# AT90USB1287 device description
Architecture: AVR8; Family: megaAVR
Registers are 8-bit, access not given, no defined reset value unless marked. A register's access mark holds for its fields unless they carry their own. Offsets are from the block's base; [hi:lo] are bit positions; {n}, {i} and the like mark numbered series; 'fields as' and 'values as' point back to an identical list.

## TC3 (TC16 module) — Timer/Counter, 16-bit
Instances: TC3 0x00
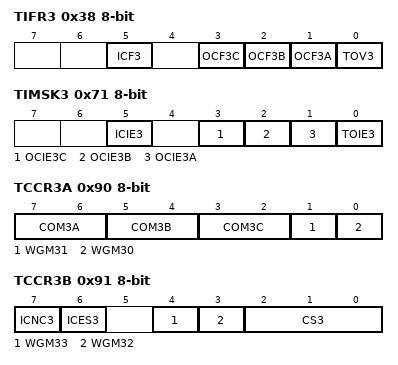
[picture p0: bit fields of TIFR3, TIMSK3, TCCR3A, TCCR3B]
0x38 TIFR3 — Timer/Counter3 Interrupt Flag register
  [5] ICF3 — Input Capture Flag 3
  [3] OCF3C — Output Compare Flag 3C
  [2] OCF3B — Output Compare Flag 3B
  [1] OCF3A — Output Compare Flag 3A
  [0] TOV3 — Timer/Counter3 Overflow Flag
0x71 TIMSK3 — Timer/Counter3 Interrupt Mask Register
  [5] ICIE3 — Timer/Counter3 Input Capture Interrupt Enable
  [3] OCIE3C — Timer/Counter3 Output Compare C Match Interrupt Enable
  [2] OCIE3B — Timer/Counter3 Output Compare B Match Interrupt Enable
  [1] OCIE3A — Timer/Counter3 Output Compare A Match Interrupt Enable
  [0] TOIE3 — Timer/Counter3 Overflow Interrupt Enable
0x90 TCCR3A — Timer/Counter3 Control Register A
  [7:6] COM3A — Compare Output Mode 1A, bits
  [5:4] COM3B — Compare Output Mode 3B, bits
  [3:2] COM3C — Compare Output Mode 3C, bits
  [1] WGM31 — Waveform Generation Mode
  [0] WGM30 — Waveform Generation Mode
0x91 TCCR3B — Timer/Counter3 Control Register B
  [7] ICNC3 — Input Capture 3 Noise Canceler
  [6] ICES3 — Input Capture 3 Edge Select
  [4] WGM33 (bit 2 of the value upward) — Waveform Generation Mode
  [3] WGM32 (bit 2 of the value upward) — Waveform Generation Mode
  [2:0] CS3 — Prescaler source of Timer/Counter 3
    0=No Clock Source (Stopped); 1=Running, No Prescaling; 2=Running, CLK/8; 3=Running, CLK/64; 4=Running, CLK/256; 5=Running, CLK/1024; 6=Running, ExtClk Tx Falling Edge; 7=Running, ExtClk Tx Rising Edge
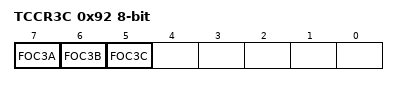
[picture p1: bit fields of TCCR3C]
0x92 TCCR3C — Timer/Counter 3 Control Register C
  [7] FOC3A — Force Output Compare 3A
  [6] FOC3B — Force Output Compare 3B
  [5] FOC3C — Force Output Compare 3C
0x94 TCNT3 16-bit — Timer/Counter3 Bytes
0x96 ICR3 16-bit — Timer/Counter3 Input Capture Register Bytes
0x98 OCR3A 16-bit — Timer/Counter3 Output Compare Register A Bytes
0x9A OCR3B 16-bit — Timer/Counter3 Output Compare Register B Bytes
0x9C OCR3C 16-bit — Timer/Counter3 Output Compare Register B Bytes

## TC1 (TC16 module) — Timer/Counter, 16-bit
Instances: TC1 0x00
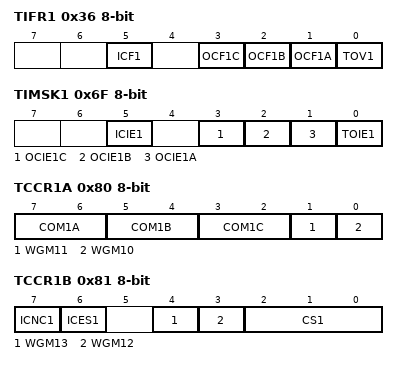
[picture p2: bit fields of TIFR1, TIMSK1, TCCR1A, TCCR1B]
0x36 TIFR1 — Timer/Counter1 Interrupt Flag register
  [5] ICF1 — Input Capture Flag 1
  [3] OCF1C — Output Compare Flag 1C
  [2] OCF1B — Output Compare Flag 1B
  [1] OCF1A — Output Compare Flag 1A
  [0] TOV1 — Timer/Counter1 Overflow Flag
0x6F TIMSK1 — Timer/Counter1 Interrupt Mask Register
  [5] ICIE1 — Timer/Counter1 Input Capture Interrupt Enable
  [3] OCIE1C — Timer/Counter1 Output Compare C Match Interrupt Enable
  [2] OCIE1B — Timer/Counter1 Output Compare B Match Interrupt Enable
  [1] OCIE1A — Timer/Counter1 Output Compare A Match Interrupt Enable
  [0] TOIE1 — Timer/Counter1 Overflow Interrupt Enable
0x80 TCCR1A — Timer/Counter1 Control Register A
  [7:6] COM1A — Compare Output Mode 1A, bits
  [5:4] COM1B — Compare Output Mode 1B, bits
  [3:2] COM1C — Compare Output Mode 1C, bits
  [1] WGM11 — Waveform Generation Mode
  [0] WGM10 — Waveform Generation Mode
0x81 TCCR1B — Timer/Counter1 Control Register B
  [7] ICNC1 — Input Capture 1 Noise Canceler
  [6] ICES1 — Input Capture 1 Edge Select
  [4] WGM13 (bit 2 of the value upward) — Waveform Generation Mode
  [3] WGM12 (bit 2 of the value upward) — Waveform Generation Mode
  [2:0] CS1 — Prescaler source of Timer/Counter 1
    0=No Clock Source (Stopped); 1=Running, No Prescaling; 2=Running, CLK/8; 3=Running, CLK/64; 4=Running, CLK/256; 5=Running, CLK/1024; 6=Running, ExtClk Tx Falling Edge; 7=Running, ExtClk Tx Rising Edge
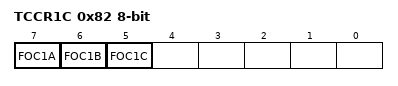
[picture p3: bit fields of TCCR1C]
0x82 TCCR1C — Timer/Counter 1 Control Register C
  [7] FOC1A — Force Output Compare 1A
  [6] FOC1B — Force Output Compare 1B
  [5] FOC1C — Force Output Compare 1C
0x84 TCNT1 16-bit — Timer/Counter1 Bytes
0x86 ICR1 16-bit — Timer/Counter1 Input Capture Register Bytes
0x88 OCR1A 16-bit — Timer/Counter1 Output Compare Register A Bytes
0x8A OCR1B 16-bit — Timer/Counter1 Output Compare Register B Bytes
0x8C OCR1C 16-bit — Timer/Counter1 Output Compare Register C Bytes

## JTAG — JTAG Interface
Instances: JTAG 0x00
0x51 OCDR — On-Chip Debug Related Register in I/O Memory
0x54 MCUSR — MCU Status Register
  [4] JTRF — JTAG Reset Flag
0x55 MCUCR — MCU Control Register
  [7] JTD — JTAG Interface Disable

## EXINT — External Interrupts
Instances: EXINT 0x00
0x3B PCIFR — Pin Change Interrupt Flag Register
  [0] PCIF0 — Pin Change Interrupt Flag 0
0x3C EIFR — External Interrupt Flag Register
  [7:0] INTF — External Interrupt Flags
0x3D EIMSK — External Interrupt Mask Register
  [7:0] INT — External Interrupt Request 7 Enable
0x68 PCICR — Pin Change Interrupt Control Register
  [0] PCIE0 — Pin Change Interrupt Enable 0
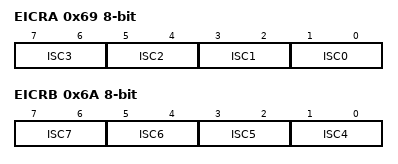
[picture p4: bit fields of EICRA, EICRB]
0x69 EICRA — External Interrupt Control Register A
  [all] fields
    0=Low Level of INTX; 1=Any Logical Change of INTX; 2=Falling Edge of INTX; 3=Rising Edge of INTX
  [2n+1:2n] ISC{n} (n=0..3) — External Interrupt Sense Control Bit
0x6A EICRB — External Interrupt Control Register B
  [all] fields
    values as the fields of EICRA
  [2n-7:2n-8] ISC{n} (n=4..7) — External Interrupt 7-4 Sense Control Bit
0x6B PCMSK0 — Pin Change Mask Register 0

## ADC — Analog-to-Digital Converter
Instances: ADC 0x00
0x78 ADC 16-bit — ADC Data Register Bytes
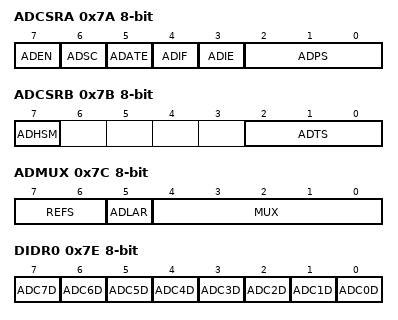
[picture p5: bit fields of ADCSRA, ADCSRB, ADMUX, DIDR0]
0x7A ADCSRA — The ADC Control and Status register
  [7] ADEN — ADC Enable
  [6] ADSC — ADC Start Conversion
  [5] ADATE — ADC Auto Trigger Enable
  [4] ADIF — ADC Interrupt Flag
  [3] ADIE — ADC Interrupt Enable
  [2:0] ADPS — ADC Prescaler Select Bits
    0=2; 1=2; 2=4; 3=8; 4=16; 5=32; 6=64; 7=128
0x7B ADCSRB — ADC Control and Status Register B
  [7] ADHSM — ADC High Speed Mode
  [2:0] ADTS — ADC Auto Trigger Sources
    0=Free Running mode; 1=Analog Comparator; 2=External Interrupt Request 0; 3=Timer/Counter0 Compare Match A; 4=Timer/Counter0 Overflow; 5=Timer/Counter1 Compare Match B; 6=Timer/Counter1 Overflow; 7=Timer/Counter1 Capture Event
0x7C ADMUX — The ADC multiplexer Selection Register
  [7:6] REFS — Reference Selection Bits
    0=AREF, Internal Vref turned off; 1=AVCC with external capacitor at AREF pin; 3=Internal 2.56V Voltage Reference with external capacitor at AREF pin
  [5] ADLAR — Left Adjust Result
  [4:0] MUX — Analog Channel and Gain Selection Bits
0x7E DIDR0 — Digital Input Disable Register 1
  [n] ADC{n}D (n=0..7) — ADC{n} Digital input Disable

## AC — Analog Comparator
Instances: AC 0x00
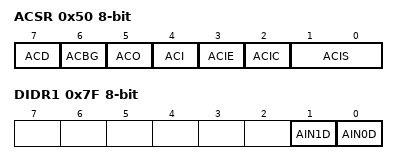
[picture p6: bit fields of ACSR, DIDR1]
0x50 ACSR — Analog Comparator Control And Status Register
  [7] ACD — Analog Comparator Disable
  [6] ACBG — Analog Comparator Bandgap Select
  [5] ACO — Analog Compare Output
  [4] ACI — Analog Comparator Interrupt Flag
  [3] ACIE — Analog Comparator Interrupt Enable
  [2] ACIC — Analog Comparator Input Capture Enable
  [1:0] ACIS — Analog Comparator Interrupt Mode Select bits
    0=Interrupt on Toggle; 2=Interrupt on Falling Edge; 3=Interrupt on Rising Edge
0x7B ADCSRB — ADC Control and Status Register B
  [6] ACME — Analog Comparator Multiplexer Enable
0x7F DIDR1
  [1] AIN1D — AIN1 Digital Input Disable
  [0] AIN0D — AIN0 Digital Input Disable

## PLL — Phase Locked Loop
Instances: PLL 0x00
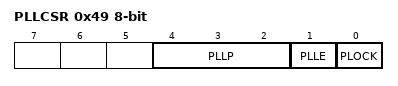
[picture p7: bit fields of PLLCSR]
0x49 PLLCSR — PLL Status and Control register
  [4:2] PLLP — PLL prescaler Bits
    3=Clock/4; 5=Clock/8
  [1] PLLE — PLL Enable Bit
  [0] PLOCK — PLL Lock Status Bit
